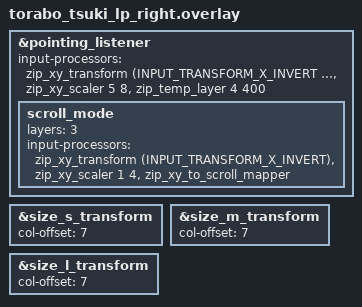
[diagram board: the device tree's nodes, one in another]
#include "torabo_tsuki_lp.dtsi"
#include <input/processors.dtsi>
#include <dt-bindings/zmk/input_transform.h>

&pointing_listener {
    input-processors = <&zip_xy_transform (INPUT_TRANSFORM_X_INVERT | INPUT_TRANSFORM_Y_INVERT)
                        &zip_xy_scaler 5 8          // 500CPI (800CPI(Default) * 5/8)
                        &zip_temp_layer 4 400>;     // トラックボール操作で Layer 4 を自動有効化（400ms でタイムアウト）

    // Layer 3 有効時: スクロールモード
    scroll_mode {
        layers = <3>;
        input-processors = <&zip_xy_transform (INPUT_TRANSFORM_X_INVERT)
                            &zip_xy_scaler 1 4          // 200CPI (800CPI(Default) * 1/4)
                            &zip_xy_to_scroll_mapper>;
    };
};

&size_s_transform {
    col-offset = <7>;
};

&size_m_transform {
    col-offset = <7>;
};

&size_l_transform {
    col-offset = <7>;
};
